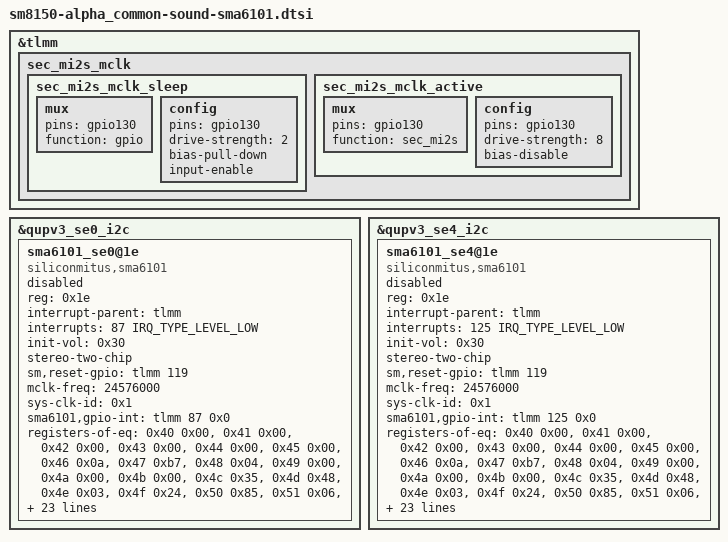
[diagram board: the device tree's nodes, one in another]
/*
 * Copyright (c) 2018, The Linux Foundation. All rights reserved.
 *
 * This program is free software; you can redistribute it and/or modify
 * it under the terms of the GNU General Public License version 2 and
 * only version 2 as published by the Free Software Foundation.
 *
 * This program is distributed in the hope that it will be useful,
 * but WITHOUT ANY WARRANTY; without even the implied warranty of
 * MERCHANTABILITY or FITNESS FOR A PARTICULAR PURPOSE.  See the
 * GNU General Public License for more details.
 */


&tlmm {
	sec_mi2s_mclk {
		sec_mi2s_mclk_sleep: sec_mi2s_mclk_sleep {
			mux {
				pins = "gpio130";
				function = "gpio";
			};

			config {
				pins = "gpio130";
				drive-strength = <2>;   /* 2 mA */
				bias-pull-down;         /* PULL DOWN */
				input-enable;
			};
		};

		sec_mi2s_mclk_active: sec_mi2s_mclk_active {
			mux {
				pins = "gpio130";
				function = "sec_mi2s";
			};

			config {
				pins = "gpio130";
				drive-strength = <8>;   /* 8 mA */
				bias-disable;           /* NO PULL */
			};
		};
	};
};

/* for Common I2C HDK */
&qupv3_se0_i2c{ /* QUPV3 SE0  */
	status = "ok";
	sma6101_se0@1e {
		compatible = "siliconmitus,sma6101";
		reg = <0x1e>;
		interrupt-parent = <&tlmm>;
		interrupts = <87 IRQ_TYPE_LEVEL_LOW>;

		init-vol = <0x30>;
		stereo-two-chip;
		sm,reset-gpio = <&tlmm 119 0x0>;

		/* Valid when sys-clk-id 0x02 */
		mclk-freq = <24576000>;
		/* SMA6101_EXTERNAL_CLOCK_19_2  : 0x00,
		* SMA6101_EXTERNAL_CLOCK_24_576 : 0x01,
		* SMA6101_PLL_CLKIN_MCLK        : 0x02,
		* SMA6101_PLL_CLKIN_BCLK        : 0x03
		*/
		sys-clk-id = <0x1>;
		/* SRC-bypass; */

		/* registers-of-amp = <0x0e 0xae>,<0x14 0x18>,<0x19 0x20>,<0x37 0x10>,<0x3c 0x30>,
				   <0x97 0xec>,
				   <0x23 0x95>,<0x24 0x0>,<0x25 0x0>,<0x26 0x78>; */
		sma6101,gpio-int= <&tlmm 87 0x0>;

		registers-of-eq = <0x40 0x00>,<0x41 0x00>,
				  <0x42 0x00>,<0x43 0x00>,
				  <0x44 0x00>,<0x45 0x00>,
				  <0x46 0x0a>,<0x47 0xb7>,
				  <0x48 0x04>,<0x49 0x00>,
				  <0x4a 0x00>,<0x4b 0x00>,
				  <0x4c 0x35>,<0x4d 0x48>,
				  <0x4e 0x03>,<0x4f 0x24>,
				  <0x50 0x85>,<0x51 0x06>,
				  <0x52 0xa3>,<0x53 0x21>,
				  <0x54 0x01>,<0x55 0x40>,
				  <0x56 0x00>,<0x57 0x00>,
				  <0x58 0xdb>,<0x59 0x7a>,
				  <0x5a 0x02>,<0x5b 0x5c>,
				  <0x5c 0xde>,<0x5d 0x07>,
				  <0x5e 0x3b>,<0x5f 0xc3>,
				  <0x60 0x06>,<0x61 0x85>,
				  <0x62 0x26>,<0x63 0x03>,
				  <0x64 0x40>,<0x65 0x3e>,
				  <0x66 0x02>,<0x67 0xc3>,
				  <0x68 0xfd>,<0x69 0x06>,
				  <0x6a 0x7a>,<0x6b 0xd9>,
				  <0x6c 0x05>,<0x6d 0x0a>,
				  <0x6e 0xef>,<0x6f 0x00>,
				  <0x70 0x09>,<0x71 0xc7>,
				  <0x72 0x07>,<0x73 0x40>,
				  <0x74 0x00>,<0x75 0x00>,
				  <0x76 0xf5>,<0x77 0x11>,
				  <0x78 0x00>,<0x79 0xf6>,
				  <0x7a 0x38>,<0x7b 0x01>,
				  <0x7c 0x28>,<0x7d 0x88>,
				  <0x7e 0x03>,<0x7f 0xaa>,
				  <0x80 0xef>,<0x81 0x02>,
				  <0x82 0x42>,<0x83 0xb0>,
				  <0x84 0x04>,<0x85 0xd4>,
				  <0x86 0xc7>,<0x87 0x00>,
				  <0x88 0x55>,<0x89 0x10>,
				  <0x8a 0x06>;
		registers-of-bo = <0x05 0xb8>,<0x06 0x38>,
				  <0x07 0x38>,<0x08 0x38>,
				  <0x0b 0x38>,<0x0c 0x38>,
				  <0x38 0x00>,<0x39 0x8c>,
				  <0x3a 0xcc>,<0xb0 0x85>,
				  <0xb1 0x8e>,<0xb2 0x89>,
				  <0xb3 0x7f>,<0xb4 0x1b>,
				  <0xb5 0x1a>,<0xb6 0x48>,
				  <0xb7 0x40>,<0xb8 0x77>,
				  <0xb9 0x76>,<0xba 0x75>,
				  <0xbb 0x6f>,<0xbc 0x19>,
				  <0xbd 0x18>,<0xbe 0x17>,
				  <0xbf 0x17>,<0x1c 0x3b>,
				  <0x1d 0x2d>,<0x1e 0x2d>,
				  <0x1f 0x2d>,<0x20 0x0f>;

		status = "disabled";
	};
};
/* for Apps I2CRev0.1 */
&qupv3_se4_i2c{ /* QUPV3 SE4  */
	sma6101_se4@1e {
		compatible = "siliconmitus,sma6101";
		reg = <0x1e>;
		interrupt-parent = <&tlmm>;
		interrupts = <125 IRQ_TYPE_LEVEL_LOW>;

		init-vol = <0x30>;
		stereo-two-chip;
		sm,reset-gpio = <&tlmm 119 0x0>;

		/* Valid when sys-clk-id 0x02 */
		mclk-freq = <24576000>;
		/* SMA6101_EXTERNAL_CLOCK_19_2  : 0x00,
		* SMA6101_EXTERNAL_CLOCK_24_576 : 0x01,
		* SMA6101_PLL_CLKIN_MCLK        : 0x02,
		* SMA6101_PLL_CLKIN_BCLK        : 0x03
		*/
		sys-clk-id = <0x1>;
		/* SRC-bypass; */

		/* registers-of-amp = <0x0e 0xae>,<0x14 0x18>,<0x19 0x20>,<0x37 0x10>,<0x3c 0x30>,
				   <0x97 0xec>,
				   <0x23 0x95>,<0x24 0x0>,<0x25 0x0>,<0x26 0x78>; */
		sma6101,gpio-int= <&tlmm 125 0x0>;

		registers-of-eq = <0x40 0x00>,<0x41 0x00>,
				  <0x42 0x00>,<0x43 0x00>,
				  <0x44 0x00>,<0x45 0x00>,
				  <0x46 0x0a>,<0x47 0xb7>,
				  <0x48 0x04>,<0x49 0x00>,
				  <0x4a 0x00>,<0x4b 0x00>,
				  <0x4c 0x35>,<0x4d 0x48>,
				  <0x4e 0x03>,<0x4f 0x24>,
				  <0x50 0x85>,<0x51 0x06>,
				  <0x52 0xa3>,<0x53 0x21>,
				  <0x54 0x01>,<0x55 0x40>,
				  <0x56 0x00>,<0x57 0x00>,
				  <0x58 0xdb>,<0x59 0x7a>,
				  <0x5a 0x02>,<0x5b 0x5c>,
				  <0x5c 0xde>,<0x5d 0x07>,
				  <0x5e 0x3b>,<0x5f 0xc3>,
				  <0x60 0x06>,<0x61 0x85>,
				  <0x62 0x26>,<0x63 0x03>,
				  <0x64 0x40>,<0x65 0x3e>,
				  <0x66 0x02>,<0x67 0xc3>,
				  <0x68 0xfd>,<0x69 0x06>,
				  <0x6a 0x7a>,<0x6b 0xd9>,
				  <0x6c 0x05>,<0x6d 0x0a>,
				  <0x6e 0xef>,<0x6f 0x00>,
				  <0x70 0x09>,<0x71 0xc7>,
				  <0x72 0x07>,<0x73 0x40>,
				  <0x74 0x00>,<0x75 0x00>,
				  <0x76 0xf5>,<0x77 0x11>,
				  <0x78 0x00>,<0x79 0xf6>,
				  <0x7a 0x38>,<0x7b 0x01>,
				  <0x7c 0x28>,<0x7d 0x88>,
				  <0x7e 0x03>,<0x7f 0xaa>,
				  <0x80 0xef>,<0x81 0x02>,
				  <0x82 0x42>,<0x83 0xb0>,
				  <0x84 0x04>,<0x85 0xd4>,
				  <0x86 0xc7>,<0x87 0x00>,
				  <0x88 0x55>,<0x89 0x10>,
				  <0x8a 0x06>;
		registers-of-bo = <0x05 0xb8>,<0x06 0x38>,
				  <0x07 0x38>,<0x08 0x38>,
				  <0x0b 0x38>,<0x0c 0x38>,
				  <0x38 0x00>,<0x39 0x8c>,
				  <0x3a 0xcc>,<0xb0 0x85>,
				  <0xb1 0x8e>,<0xb2 0x89>,
				  <0xb3 0x7f>,<0xb4 0x1b>,
				  <0xb5 0x1a>,<0xb6 0x48>,
				  <0xb7 0x40>,<0xb8 0x77>,
				  <0xb9 0x76>,<0xba 0x75>,
				  <0xbb 0x6f>,<0xbc 0x19>,
				  <0xbd 0x18>,<0xbe 0x17>,
				  <0xbf 0x17>,<0x1c 0x3b>,
				  <0x1d 0x2d>,<0x1e 0x2d>,
				  <0x1f 0x2d>,<0x20 0x0f>;

		status = "disabled";
	};
};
